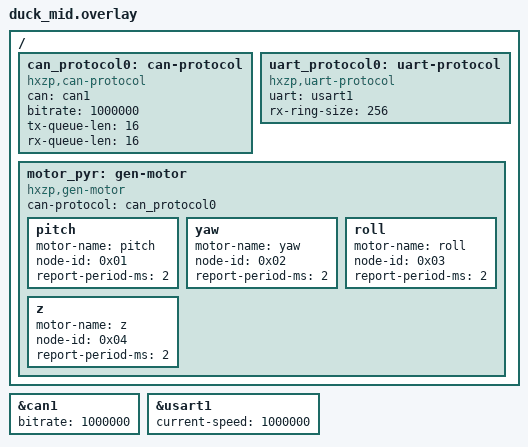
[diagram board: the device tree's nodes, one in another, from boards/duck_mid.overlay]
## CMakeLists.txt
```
# SPDX-License-Identifier: Apache-2.0

cmake_minimum_required(VERSION 3.20.0)

list(APPEND ZEPHYR_EXTRA_MODULES
    ${CMAKE_CURRENT_SOURCE_DIR}/../../zephyr-hxzp
)

find_package(Zephyr REQUIRED HINTS $ENV{ZEPHYR_BASE})
project(duck_mid)

file(GLOB_RECURSE APP_SOURCES CONFIGURE_DEPENDS
    "src/*.c"
    "src/*.cpp"
)

list(FILTER APP_SOURCES EXCLUDE REGEX ".*/src/can_protocol\\.c$")

if(NOT CONFIG_SHELL)
    list(FILTER APP_SOURCES EXCLUDE REGEX ".*/src/debug_shell\\.c$")
endif()

target_sources(app PRIVATE
    ${APP_SOURCES}
)
```

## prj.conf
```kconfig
CONFIG_PRINTK=y
CONFIG_LOG=y

CONFIG_MAIN_STACK_SIZE=2048
CONFIG_STATIC_INIT_GNU=y
# CONFIG_HW_STACK_PROTECTION=y
# C++ 支持
CONFIG_CPP=y
CONFIG_HEAP_MEM_POOL_SIZE=0
CONFIG_THREAD_NAME=n
# 标准库
CONFIG_NEWLIB_LIBC=y
CONFIG_REQUIRES_FULL_LIBC=y

CONFIG_USE_SEGGER_RTT=y
CONFIG_SEGGER_RTT_MAX_NUM_UP_BUFFERS=1
CONFIG_SEGGER_RTT_MAX_NUM_DOWN_BUFFERS=1
CONFIG_SEGGER_RTT_BUFFER_SIZE_UP=1024
CONFIG_SEGGER_RTT_BUFFER_SIZE_DOWN=16

# enable console
CONFIG_CONSOLE=y
# CONFIG_UART_CONSOLE=y
CONFIG_RTT_CONSOLE=y
CONFIG_SHELL=n

CONFIG_LOG_BACKEND_RTT=y
CONFIG_LOG_BACKEND_SHOW_COLOR=n
CONFIG_LOG_BACKEND_RTT_OUTPUT_BUFFER_SIZE=128
CONFIG_LOG_RUNTIME_FILTERING=n
CONFIG_LOG_DEFAULT_LEVEL=3

CONFIG_CAN=y 
# CONFIG_CAN_LOOPBACK=y

CONFIG_HXZP_CAN_PROTOCOL=y
CONFIG_HXZP_GEN_MOTOR=y
CONFIG_HXZP_UART_PROTOCOL=y

# LED Strip 驱动
CONFIG_LED_STRIP=y
CONFIG_WS2812_STRIP_SPI=y

# SPI 驱动
CONFIG_SPI=y

CONFIG_UART_INTERRUPT_DRIVEN=y
CONFIG_DMA=y
CONFIG_DMA_STM32=y
```

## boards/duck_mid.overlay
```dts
&can1 {
	bitrate = <1000000>;
};

&usart1 {
	current-speed = <1000000>;
};

/ {
	can_protocol0: can-protocol {
		compatible = "hxzp,can-protocol";
		status = "okay";
		can = <&can1>;
		bitrate = <1000000>;
		tx-queue-len = <16>;
		rx-queue-len = <16>;
	};

	uart_protocol0: uart-protocol {
		compatible = "hxzp,uart-protocol";
		status = "okay";
		uart = <&usart1>;
		rx-ring-size = <256>;
	};

	motor_pyr: gen-motor {
		compatible = "hxzp,gen-motor";
		status = "okay";
		can-protocol = <&can_protocol0>;

		pitch {
			motor-name = "pitch";
			node-id = <0x01>;
			report-period-ms = <2>;
		};

		yaw {
			motor-name = "yaw";
			node-id = <0x02>;
			report-period-ms = <2>;
		};

		roll {
			motor-name = "roll";
			node-id = <0x03>;
			report-period-ms = <2>;
		};

		z {
			motor-name = "z";
			node-id = <0x04>;
			report-period-ms = <2>;
		};
	};
};
```

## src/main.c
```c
/**
 * @file main.c
 * @brief Duck Mid 应用入口。
 */
#include <zephyr/kernel.h>
#include <zephyr/logging/log.h>

#include "can_command.h"
#include "gimbal.h"
#include "led.h"
#include "motor.h"
#include "uart_command.h"

LOG_MODULE_REGISTER(main_module, LOG_LEVEL_INF);

/** @brief 主循环休眠周期，单位毫秒。 */
#define MAIN_LOOP_SLEEP_MS 20

/**
 * @brief 应用主入口。
 * @return int 始终返回 0。
 * @note 主循环只负责保持系统运行，电机 demo 已移除。
 */
int main(void)
{
    int ret;

    LOG_INF("Hello, Duck!!!");

    ret = led_init();

    if (ret < 0)
    {
        LOG_WRN("LED init failed: %d", ret);
    }
    else
    {
        led_boot_blink();
    }

    ret = uart_command_init();

    if (ret < 0)
    {
        LOG_WRN("UART command init failed: %d", ret);
    }

    ret = motor_init();

    if (ret < 0)
    {
        LOG_WRN("Motor init failed: %d", ret);
    }

    ret = gimbal_init();

    if (ret < 0)
    {
        LOG_WRN("Gimbal init failed: %d", ret);
    }

    ret = can_command_init();

    if (ret < 0)
    {
        LOG_WRN("CAN command init failed: %d", ret);
    }

    while (1)
    {
        k_sleep(K_MSEC(MAIN_LOOP_SLEEP_MS));
    }

    return 0;
}
```

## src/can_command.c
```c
/**
 * @file can_command.c
 * @brief CAN 业务调试命令实现。
 */
#include "can_command.h"

#include "gimbal.h"

#include <errno.h>
#include <stdbool.h>
#include <stdint.h>

#include <zephyr/device.h>
#include <zephyr/devicetree.h>
#include <zephyr/drivers/can.h>
#include <zephyr/drivers/can_protocol.h>
#include <zephyr/kernel.h>
#include <zephyr/logging/log.h>
#include <zephyr/sys/byteorder.h>

LOG_MODULE_REGISTER(can_command, LOG_LEVEL_INF);

/** @brief mid 端云台调试请求 CAN ID。 */
#define CAN_COMMAND_GIMBAL_REQUEST_ID 0x300U

/** @brief mid 端云台调试响应 CAN ID。 */
#define CAN_COMMAND_GIMBAL_RESPONSE_ID 0x301U

/** @brief CAN 业务调试响应负载长度。 */
#define CAN_COMMAND_RESPONSE_DLC 8U

/** @brief CAN 业务调试命令最小负载长度。 */
#define CAN_COMMAND_MIN_DLC 1U

/** @brief CAN 协议设备节点。 */
#define CAN_COMMAND_PROTOCOL_NODE DT_NODELABEL(can_protocol0)

/** @brief PID 字段编号中 loop 字段偏移。 */
#define CAN_COMMAND_PID_LOOP_SHIFT 4U

/** @brief PID 字段编号中 field 字段掩码。 */
#define CAN_COMMAND_PID_FIELD_MASK 0x0FU

/**
 * @brief CAN 业务调试命令码。
 */
enum can_command_gimbal_cmd
{
    /**< 设置单轴目标角度。 */
    CAN_COMMAND_GIMBAL_CMD_SET_AXIS_TARGET = 0x01,
    /**< 关闭云台输出。 */
    CAN_COMMAND_GIMBAL_CMD_DISABLE = 0x02,
    /**< 设置 PID 单个字段。 */
    CAN_COMMAND_GIMBAL_CMD_SET_PID_FIELD = 0x10,
    /**< 读取 PID 单个字段。 */
    CAN_COMMAND_GIMBAL_CMD_GET_PID_FIELD = 0x11,
};

/**
 * @brief CAN 业务调试状态码。
 */
enum can_command_status
{
    /**< 命令成功。 */
    CAN_COMMAND_STATUS_OK = 0x00,
    /**< 命令非法。 */
    CAN_COMMAND_STATUS_INVALID_CMD = 0x01,
    /**< 参数非法。 */
    CAN_COMMAND_STATUS_INVALID_PARAM = 0x02,
    /**< 执行失败。 */
    CAN_COMMAND_STATUS_EXEC_FAILED = 0x03,
};

/**
 * @brief PID 可调字段编号。
 */
enum can_command_pid_field
{
    /**< 比例增益。 */
    CAN_COMMAND_PID_FIELD_KP = 0x00,
    /**< 积分增益。 */
    CAN_COMMAND_PID_FIELD_KI = 0x01,
    /**< 微分增益。 */
    CAN_COMMAND_PID_FIELD_KD = 0x02,
    /**< 积分限幅百分比。 */
    CAN_COMMAND_PID_FIELD_INTEGRAL_LIMIT_PERCENT = 0x03,
    /**< 输出限幅百分比。 */
    CAN_COMMAND_PID_FIELD_OUTPUT_LIMIT_PERCENT = 0x04,
};

/** @brief CAN 协议设备。 */
static const struct device *const can_command_protocol_dev =
    DEVICE_DT_GET(CAN_COMMAND_PROTOCOL_NODE);

/** @brief CAN 业务调试过滤器句柄。 */
static int can_command_filter_handle = -1;

/**
 * @brief 将内部错误码转换为 CAN 业务调试状态码。
 * @param ret 内部错误码。
 * @return uint8_t CAN 业务调试状态码。
 */
static uint8_t can_command_status_from_ret(int ret)
{
    if (ret == 0)
    {
        return CAN_COMMAND_STATUS_OK;
    }

    if ((ret == -EINVAL) || (ret == -EMSGSIZE))
    {
        return CAN_COMMAND_STATUS_INVALID_PARAM;
    }

    return CAN_COMMAND_STATUS_EXEC_FAILED;
}

/**
 * @brief 判断云台轴编号是否有效。
 * @param axis_id 云台轴编号。
 * @return bool true 表示有效，false 表示无效。
 */
static bool can_command_axis_id_is_valid(uint8_t axis_id)
{
    if (axis_id >= (uint8_t)GIMBAL_AXIS_COUNT)
    {
        return false;
    }

    return true;
}

/**
 * @brief 判断 PID 环编号是否有效。
 * @param loop PID 环编号。
 * @return bool true 表示有效，false 表示无效。
 */
static bool can_command_pid_loop_is_valid(uint8_t loop)
{
    if ((loop == (uint8_t)GIMBAL_PID_LOOP_POSITION) ||
        (loop == (uint8_t)GIMBAL_PID_LOOP_SPEED))
    {
        return true;
    }

    return false;
}

/**
 * @brief 判断 PID 字段编号是否有效。
 * @param field PID 字段编号。
 * @return bool true 表示有效，false 表示无效。
 */
static bool can_command_pid_field_is_valid(uint8_t field)
{
    if (field <= (uint8_t)CAN_COMMAND_PID_FIELD_OUTPUT_LIMIT_PERCENT)
    {
        return true;
    }

    return false;
}

/**
 * @brief 从 CAN PID 字段描述中解析 PID 环和字段编号。
 * @param packed CAN PID 字段描述。
 * @param loop 输出 PID 环编号。
 * @param field 输出 PID 字段编号。
 * @return int 0 表示成功，负值表示失败。
 */
static int can_command_parse_pid_selector(uint8_t packed,
                                          enum gimbal_pid_loop *loop,
                                          uint8_t *field)
{
    uint8_t raw_loop;
    uint8_t raw_field;

    if ((loop == NULL) || (field == NULL))
    {
        return -EINVAL;
    }

    raw_loop = packed >> CAN_COMMAND_PID_LOOP_SHIFT;
    raw_field = packed & CAN_COMMAND_PID_FIELD_MASK;

    if (!can_command_pid_loop_is_valid(raw_loop))
    {
        return -EINVAL;
    }

    if (!can_command_pid_field_is_valid(raw_field))
    {
        return -EINVAL;
    }

    *loop = (enum gimbal_pid_loop)raw_loop;
    *field = raw_field;

    return 0;
}

/**
 * @brief 从 PID 百分比配置中读取指定字段。
 * @param config PID 百分比配置。
 * @param field PID 字段编号。
 * @param value 输出字段值。
 * @return int 0 表示成功，负值表示失败。
 */
static int can_command_get_pid_field_value(const struct gimbal_pid_percent_config *config,
                                           uint8_t field,
                                           int32_t *value)
{
    if ((config == NULL) || (value == NULL))
    {
        return -EINVAL;
    }

    switch (field)
    {
    case CAN_COMMAND_PID_FIELD_KP:
        *value = config->kp;
        return 0;

    case CAN_COMMAND_PID_FIELD_KI:
        *value = config->ki;
        return 0;

    case CAN_COMMAND_PID_FIELD_KD:
        *value = config->kd;
        return 0;

    case CAN_COMMAND_PID_FIELD_INTEGRAL_LIMIT_PERCENT:
        *value = (int32_t)config->integral_limit_percent;
        return 0;

    case CAN_COMMAND_PID_FIELD_OUTPUT_LIMIT_PERCENT:
        *value = (int32_t)config->output_limit_percent;
        return 0;

    default:
        break;
    }

    return -EINVAL;
}

/**
 * @brief 向 PID 百分比配置写入指定字段。
 * @param config PID 百分比配置。
 * @param field PID 字段编号。
 * @param value 字段值。
 * @return int 0 表示成功，负值表示失败。
 */
static int can_command_set_pid_field_value(struct gimbal_pid_percent_config *config,
                                           uint8_t field,
                                           int32_t value)
{
    if (config == NULL)
    {
        return -EINVAL;
    }

    switch (field)
    {
    case CAN_COMMAND_PID_FIELD_KP:
        config->kp = value;
        return 0;

    case CAN_COMMAND_PID_FIELD_KI:
        config->ki = value;
        return 0;

    case CAN_COMMAND_PID_FIELD_KD:
        config->kd = value;
        return 0;

    case CAN_COMMAND_PID_FIELD_INTEGRAL_LIMIT_PERCENT:
        if (value < 0)
        {
            return -EINVAL;
        }

        config->integral_limit_percent = (uint32_t)value;
        return 0;

    case CAN_COMMAND_PID_FIELD_OUTPUT_LIMIT_PERCENT:
        if (value < 0)
        {
            return -EINVAL;
        }

        config->output_limit_percent = (uint32_t)value;
        return 0;

    default:
        break;
    }

    return -EINVAL;
}

/**
 * @brief 发送 CAN 业务调试响应。
 * @param cmd 命令码。
 * @param status 状态码。
 * @param axis_id 云台轴编号。
 * @param packed_selector PID 字段描述或保留字段。
 * @param value 响应数值。
 * @return int 0 表示成功，负值表示失败。
 */
static int can_command_send_response(uint8_t cmd,
                                     uint8_t status,
                                     uint8_t axis_id,
                                     uint8_t packed_selector,
                                     int32_t value)
{
    uint8_t payload[CAN_COMMAND_RESPONSE_DLC] = {0};

    payload[0] = cmd;
    payload[1] = status;
    payload[2] = axis_id;
    payload[3] = packed_selector;
    sys_put_le32((uint32_t)value, &payload[4]);

    return can_protocol_send_data(can_command_protocol_dev,
                                  CAN_COMMAND_GIMBAL_RESPONSE_ID,
                                  payload,
                                  CAN_COMMAND_RESPONSE_DLC);
}

/**
 * @brief 处理设置单轴目标角度命令。
 * @param frame CAN 报文。
 * @return int 0 表示成功，负值表示失败。
 */
static int can_command_handle_set_axis_target(const struct can_frame *frame)
{
    uint8_t axis_id;
    int32_t target_mrad;
    int ret;

    if ((frame == NULL) || (frame->dlc < 6U))
    {
        return -EINVAL;
    }

    axis_id = frame->data[1];
    target_mrad = (int32_t)sys_get_le32(&frame->data[2]);

    if (!can_command_axis_id_is_valid(axis_id))
    {
        return -EINVAL;
    }

    ret = gimbal_set_axis_target((enum gimbal_axis_id)axis_id,
                                 target_mrad,
                                 GIMBAL_TARGET_SOURCE_EXTERNAL);

    if (ret < 0)
    {
        return ret;
    }

    return can_command_send_response(frame->data[0],
                                     CAN_COMMAND_STATUS_OK,
                                     axis_id,
                                     0U,
                                     target_mrad);
}

/**
 * @brief 处理关闭云台输出命令。
 * @param frame CAN 报文。
 * @return int 0 表示成功，负值表示失败。
 */
static int can_command_handle_disable(const struct can_frame *frame)
{
    int ret;

    if (frame == NULL)
    {
        return -EINVAL;
    }

    ret = gimbal_disable();

    if (ret < 0)
    {
        return ret;
    }

    return can_command_send_response(frame->data[0],
                                     CAN_COMMAND_STATUS_OK,
                                     0U,
                                     0U,
                                     0);
}

/**
 * @brief 处理设置 PID 单字段命令。
 * @param frame CAN 报文。
 * @return int 0 表示成功，负值表示失败。
 */
static int can_command_handle_set_pid_field(const struct can_frame *frame)
{
    struct gimbal_pid_percent_config config;
    enum gimbal_pid_loop loop;
    uint8_t axis_id;
    uint8_t packed_selector;
    uint8_t field;
    int32_t value;
    int ret;

    if ((frame == NULL) || (frame->dlc < 8U))
    {
        return -EINVAL;
    }

    axis_id = frame->data[1];
    packed_selector = frame->data[2];
    value = (int32_t)sys_get_le32(&frame->data[3]);

    if (!can_command_axis_id_is_valid(axis_id))
    {
        return -EINVAL;
    }

    ret = can_command_parse_pid_selector(packed_selector, &loop, &field);

    if (ret < 0)
    {
        return ret;
    }

    ret = gimbal_get_pid_percent_config((enum gimbal_axis_id)axis_id, loop, &config);

    if (ret < 0)
    {
        return ret;
    }

    ret = can_command_set_pid_field_value(&config, field, value);

    if (ret < 0)
    {
        return ret;
    }

    ret = gimbal_set_pid_percent_config((enum gimbal_axis_id)axis_id, loop, &config);

    if (ret < 0)
    {
        return ret;
    }

    return can_command_send_response(frame->data[0],
                                     CAN_COMMAND_STATUS_OK,
                                     axis_id,
                                     packed_selector,
                                     value);
}

/**
 * @brief 处理读取 PID 单字段命令。
 * @param frame CAN 报文。
 * @return int 0 表示成功，负值表示失败。
 */
static int can_command_handle_get_pid_field(const struct can_frame *frame)
{
    struct gimbal_pid_percent_config config;
    enum gimbal_pid_loop loop;
    uint8_t axis_id;
    uint8_t packed_selector;
    uint8_t field;
    int32_t value;
    int ret;

    if ((frame == NULL) || (frame->dlc < 3U))
    {
        return -EINVAL;
    }

    axis_id = frame->data[1];
    packed_selector = frame->data[2];

    if (!can_command_axis_id_is_valid(axis_id))
    {
        return -EINVAL;
    }

    ret = can_command_parse_pid_selector(packed_selector, &loop, &field);

    if (ret < 0)
    {
        return ret;
    }

    ret = gimbal_get_pid_percent_config((enum gimbal_axis_id)axis_id, loop, &config);

    if (ret < 0)
    {
        return ret;
    }

    ret = can_command_get_pid_field_value(&config, field, &value);

    if (ret < 0)
    {
        return ret;
    }

    return can_command_send_response(frame->data[0],
                                     CAN_COMMAND_STATUS_OK,
                                     axis_id,
                                     packed_selector,
                                     value);
}

/**
 * @brief 处理云台 CAN 业务调试报文。
 * @param frame CAN 报文。
 * @return int 0 表示成功，负值表示失败。
 */
static int can_command_handle_gimbal_frame(const struct can_frame *frame)
{
    if ((frame == NULL) || (frame->dlc < CAN_COMMAND_MIN_DLC))
    {
        return -EINVAL;
    }

    switch (frame->data[0])
    {
    case CAN_COMMAND_GIMBAL_CMD_SET_AXIS_TARGET:
        return can_command_handle_set_axis_target(frame);

    case CAN_COMMAND_GIMBAL_CMD_DISABLE:
        return can_command_handle_disable(frame);

    case CAN_COMMAND_GIMBAL_CMD_SET_PID_FIELD:
        return can_command_handle_set_pid_field(frame);

    case CAN_COMMAND_GIMBAL_CMD_GET_PID_FIELD:
        return can_command_handle_get_pid_field(frame);

    default:
        break;
    }

    return -ENOTSUP;
}

/**
 * @brief CAN 业务调试接收回调。
 * @param frame 接收到的 CAN 报文。
 * @param user_data 用户参数。
 * @return void
 */
static void can_command_rx_handler(const struct can_frame *frame, void *user_data)
{
    uint8_t status;
    uint8_t cmd = 0U;
    uint8_t axis_id = 0U;
    uint8_t packed_selector = 0U;
    int ret;

    ARG_UNUSED(user_data);

    if ((frame != NULL) && (frame->dlc > 0U))
    {
        cmd = frame->data[0];

        if (frame->dlc > 1U)
        {
            axis_id = frame->data[1];
        }

        if (frame->dlc > 2U)
        {
            packed_selector = frame->data[2];
        }
    }

    ret = can_command_handle_gimbal_frame(frame);

    if (ret < 0)
    {
        if (ret == -ENOTSUP)
        {
            status = CAN_COMMAND_STATUS_INVALID_CMD;
        }
        else
        {
            status = can_command_status_from_ret(ret);
        }

        can_command_send_response(cmd, status, axis_id, packed_selector, ret);
    }
}

/**
 * @brief 初始化 CAN 业务调试命令模块。
 * @return int 0 表示成功，负值表示失败。
 */
int can_command_init(void)
{
    struct can_protocol_filter_config filter = {
        .id = CAN_COMMAND_GIMBAL_REQUEST_ID,
        .mask = CAN_STD_ID_MASK,
        .flags = 0U,
    };

    if (!device_is_ready(can_command_protocol_dev))
    {
        return -ENODEV;
    }

    if (can_command_filter_handle >= 0)
    {
        return 0;
    }

    can_command_filter_handle = can_protocol_add_rx_filter(can_command_protocol_dev,
                                                           &filter,
                                                           can_command_rx_handler,
                                                           NULL);

    if (can_command_filter_handle < 0)
    {
        return can_command_filter_handle;
    }

    LOG_INF("CAN gimbal debug ready: req=0x%03x rsp=0x%03x",
            CAN_COMMAND_GIMBAL_REQUEST_ID,
            CAN_COMMAND_GIMBAL_RESPONSE_ID);

    return 0;
}
```

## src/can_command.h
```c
/**
 * @file can_command.h
 * @brief CAN 业务调试命令接口。
 */
#ifndef CAN_COMMAND_H_
#define CAN_COMMAND_H_

#ifdef __cplusplus
extern "C"
{
#endif

/**
 * @brief 初始化 CAN 业务调试命令模块。
 * @return int 0 表示成功，负值表示失败。
 */
int can_command_init(void);

#ifdef __cplusplus
}
#endif

#endif /* CAN_COMMAND_H_ */
```

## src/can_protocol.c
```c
/**
 * @file can_protocol.c
 * @brief CAN 传输层实现。
 */
#include "can_protocol.h"

#include <errno.h>
#include <string.h>

#include <zephyr/device.h>
#include <zephyr/devicetree.h>
#include <zephyr/kernel.h>
#include <zephyr/logging/log.h>

LOG_MODULE_REGISTER(can_protocol, LOG_LEVEL_INF);

/** @brief 默认 CAN 波特率，单位 bit/s。 */
#define CAN_PROTOCOL_BAUDRATE 1000000U

/** @brief 接收消息队列长度。 */
#define CAN_PROTOCOL_RX_QUEUE_LEN 16

/** @brief 发送消息队列长度。 */
#define CAN_PROTOCOL_TX_QUEUE_LEN 16

/** @brief 发送入队等待时间。 */
#define CAN_PROTOCOL_TX_QUEUE_TIMEOUT K_MSEC(100)

/** @brief 发送超时时间。 */
#define CAN_PROTOCOL_TX_TIMEOUT K_MSEC(100)

/** @brief 无效过滤器 ID。 */
#define CAN_PROTOCOL_INVALID_FILTER_ID (-1)

/** @brief 接收线程栈大小。 */
#define CAN_PROTOCOL_THREAD_STACK_SIZE 1024

/** @brief 发送线程栈大小。 */
#define CAN_PROTOCOL_TX_THREAD_STACK_SIZE 1024

/** @brief 接收线程优先级。 */
#define CAN_PROTOCOL_THREAD_PRIORITY 5

/** @brief 发送线程优先级，数值越大优先级越低。 */
#define CAN_PROTOCOL_TX_THREAD_PRIORITY 6

/** @brief CAN 接收消息队列。 */
CAN_MSGQ_DEFINE(can_protocol_rx_msgq, CAN_PROTOCOL_RX_QUEUE_LEN);

/** @brief CAN 发送消息队列。 */
CAN_MSGQ_DEFINE(can_protocol_tx_msgq, CAN_PROTOCOL_TX_QUEUE_LEN);

/** @brief 当前使用的 CAN 控制器设备。 */
static const struct device *const can_dev = DEVICE_DT_GET(DT_NODELABEL(can1));

/** @brief 当前安装的过滤器 ID 列表。 */
static int can_protocol_filter_ids[CAN_PROTOCOL_MAX_FILTER_COUNT];

/** @brief 当前安装的过滤器数量。 */
static size_t can_protocol_filter_count;

/** @brief 接收回调函数。 */
static can_protocol_rx_handler_t can_protocol_rx_handler;

/** @brief 接收回调的用户参数。 */
static void *can_protocol_rx_user_data;

/** @brief 传输层是否已经初始化。 */
static bool can_protocol_initialized;

/** @brief 接收线程是否已经启动。 */
static bool can_protocol_thread_started;

/** @brief 发送线程是否已经启动。 */
static bool can_protocol_tx_thread_started;

/** @brief 传输层互斥锁。 */
K_MUTEX_DEFINE(can_protocol_mutex);

/** @brief 接收线程栈。 */
K_THREAD_STACK_DEFINE(can_protocol_thread_stack, CAN_PROTOCOL_THREAD_STACK_SIZE);

/** @brief 接收线程控制块。 */
static struct k_thread can_protocol_thread_data;

/** @brief 发送线程栈。 */
K_THREAD_STACK_DEFINE(can_protocol_tx_thread_stack, CAN_PROTOCOL_TX_THREAD_STACK_SIZE);

/** @brief 发送线程控制块。 */
static struct k_thread can_protocol_tx_thread_data;

/**
 * @brief 重置过滤器记录。
 * @return void
 */
static void can_protocol_reset_filter_records(void)
{
    size_t i;

    for (i = 0U; i < CAN_PROTOCOL_MAX_FILTER_COUNT; i++)
    {
        can_protocol_filter_ids[i] = CAN_PROTOCOL_INVALID_FILTER_ID;
    }

    can_protocol_filter_count = 0U;
}

/**
 * @brief 移除当前已安装的所有过滤器。
 * @return void
 */
static void can_protocol_remove_filters(void)
{
    size_t i;

    for (i = 0U; i < can_protocol_filter_count; i++)
    {
        if (can_protocol_filter_ids[i] >= 0)
        {
            can_remove_rx_filter(can_dev, can_protocol_filter_ids[i]);
            can_protocol_filter_ids[i] = CAN_PROTOCOL_INVALID_FILTER_ID;
        }
    }

    can_protocol_filter_count = 0U;
}

/**
 * @brief 安装 CAN 接收过滤器。
 * @param filters 过滤器配置列表。
 * @param filter_count 过滤器数量。
 * @return int 0 表示成功，负值表示失败。
 */
static int can_protocol_add_filters(const struct can_protocol_filter_config *filters,
                                    size_t filter_count)
{
    size_t i;

    can_protocol_reset_filter_records();

    for (i = 0U; i < filter_count; i++)
    {
        const struct can_filter filter = {
            .id = filters[i].id,
            .mask = filters[i].mask,
            .flags = filters[i].flags,
        };
        int ret;

        ret = can_add_rx_filter_msgq(can_dev, &can_protocol_rx_msgq, &filter);

        if (ret < 0)
        {
            can_protocol_remove_filters();
            return ret;
        }

        can_protocol_filter_ids[i] = ret;
        can_protocol_filter_count++;
    }

    return 0;
}

/**
 * @brief CAN 控制器状态变化回调。
 * @param dev CAN 设备指针。
 * @param state 新的总线状态。
 * @param err_cnt 当前总线错误计数。
 * @param user_data 用户参数。
 * @return void
 */
static void can_protocol_state_change_cb(const struct device *dev,
                                         enum can_state state,
                                         struct can_bus_err_cnt err_cnt,
                                         void *user_data)
{
    ARG_UNUSED(dev);
    ARG_UNUSED(user_data);

    LOG_WRN("CAN state changed: state=%d tx_err=%u rx_err=%u",
            state,
            err_cnt.tx_err_cnt,
            err_cnt.rx_err_cnt);
}

/**
 * @brief CAN 接收线程入口。
 * @param arg1 线程参数 1。
 * @param arg2 线程参数 2。
 * @param arg3 线程参数 3。
 * @return void
 */
static void can_protocol_thread_entry(void *arg1, void *arg2, void *arg3)
{
    ARG_UNUSED(arg1);
    ARG_UNUSED(arg2);
    ARG_UNUSED(arg3);

    while (1)
    {
        struct can_frame frame;
        can_protocol_rx_handler_t rx_handler;
        void *user_data;

        if (k_msgq_get(&can_protocol_rx_msgq, &frame, K_FOREVER) != 0)
        {
            continue;
        }

        k_mutex_lock(&can_protocol_mutex, K_FOREVER);

        if (!can_protocol_initialized || (can_protocol_rx_handler == NULL))
        {
            k_mutex_unlock(&can_protocol_mutex);
            continue;
        }

        rx_handler = can_protocol_rx_handler;
        user_data = can_protocol_rx_user_data;
        k_mutex_unlock(&can_protocol_mutex);

        rx_handler(&frame, user_data);
    }
}

/**
 * @brief CAN 发送线程入口。
 * @param arg1 线程参数 1。
 * @param arg2 线程参数 2。
 * @param arg3 线程参数 3。
 * @return void
 */
static void can_protocol_tx_thread_entry(void *arg1, void *arg2, void *arg3)
{
    ARG_UNUSED(arg1);
    ARG_UNUSED(arg2);
    ARG_UNUSED(arg3);

    while (1)
    {
        struct can_frame frame;
        bool initialized;
        int ret;

        if (k_msgq_get(&can_protocol_tx_msgq, &frame, K_FOREVER) != 0)
        {
            continue;
        }

        k_mutex_lock(&can_protocol_mutex, K_FOREVER);
        initialized = can_protocol_initialized;
        k_mutex_unlock(&can_protocol_mutex);

        if (!initialized)
        {
            continue;
        }

        ret = can_send(can_dev, &frame, CAN_PROTOCOL_TX_TIMEOUT, NULL, NULL);

        if (ret < 0)
        {
            LOG_ERR("CAN send failed: id=0x%03x ret=%d", frame.id, ret);
        }
    }
}

/**
 * @brief 启动 CAN 接收线程。
 * @return int 0 表示成功，负值表示失败。
 */
static int can_protocol_start_thread(void)
{
    if (can_protocol_thread_started)
    {
        return 0;
    }

    k_thread_create(&can_protocol_thread_data,
                    can_protocol_thread_stack,
                    K_THREAD_STACK_SIZEOF(can_protocol_thread_stack),
                    can_protocol_thread_entry,
                    NULL,
                    NULL,
                    NULL,
                    CAN_PROTOCOL_THREAD_PRIORITY,
                    0,
                    K_NO_WAIT);

    can_protocol_thread_started = true;
    return 0;
}

/**
 * @brief 启动 CAN 发送线程。
 * @return int 0 表示成功，负值表示失败。
 */
static int can_protocol_start_tx_thread(void)
{
    if (can_protocol_tx_thread_started)
    {
        return 0;
    }

    k_thread_create(&can_protocol_tx_thread_data,
                    can_protocol_tx_thread_stack,
                    K_THREAD_STACK_SIZEOF(can_protocol_tx_thread_stack),
                    can_protocol_tx_thread_entry,
                    NULL,
                    NULL,
                    NULL,
                    CAN_PROTOCOL_TX_THREAD_PRIORITY,
                    0,
                    K_NO_WAIT);

    can_protocol_tx_thread_started = true;
    return 0;
}

/**
 * @brief 初始化 CAN 传输层。
 * @param filters 过滤器配置列表。
 * @param filter_count 过滤器数量。
 * @param rx_handler 接收回调函数。
 * @param user_data 传递给接收回调的用户参数。
 * @return int 0 表示成功，负值表示失败。
 */
int can_protocol_init(const struct can_protocol_filter_config *filters,
                      size_t filter_count,
                      can_protocol_rx_handler_t rx_handler,
                      void *user_data)
{
    int ret;

    if ((filters == NULL) || (filter_count == 0U) ||
        (filter_count > CAN_PROTOCOL_MAX_FILTER_COUNT) ||
        (rx_handler == NULL))
    {
        return -EINVAL;
    }

    if (!device_is_ready(can_dev))
    {
        return -ENODEV;
    }

    ret = can_protocol_start_thread();

    if (ret < 0)
    {
        return ret;
    }

    ret = can_protocol_start_tx_thread();

    if (ret < 0)
    {
        return ret;
    }

    if (can_protocol_initialized)
    {
        can_protocol_deinit();
    }

    k_mutex_lock(&can_protocol_mutex, K_FOREVER);
    can_protocol_rx_handler = rx_handler;
    can_protocol_rx_user_data = user_data;
    can_protocol_initialized = false;
    k_msgq_purge(&can_protocol_rx_msgq);
    k_msgq_purge(&can_protocol_tx_msgq);
    can_protocol_reset_filter_records();
    k_mutex_unlock(&can_protocol_mutex);

    ret = can_stop(can_dev);

    if ((ret < 0) && (ret != -EALREADY))
    {
        return ret;
    }

    /*
     * CAN_MODE_NORMAL 不包含 CAN_MODE_ONE_SHOT，控制器会保持自动重传。
     */
    ret = can_set_mode(can_dev, CAN_MODE_NORMAL);

    if (ret < 0)
    {
        return ret;
    }

    ret = can_set_bitrate(can_dev, CAN_PROTOCOL_BAUDRATE);

    if (ret < 0)
    {
        return ret;
    }

    can_set_state_change_callback(can_dev, can_protocol_state_change_cb, NULL);

    ret = can_start(can_dev);

    if (ret < 0)
    {
        can_set_state_change_callback(can_dev, NULL, NULL);
        return ret;
    }

    ret = can_protocol_add_filters(filters, filter_count);

    if (ret < 0)
    {
        can_set_state_change_callback(can_dev, NULL, NULL);
        can_stop(can_dev);
        return ret;
    }

    k_mutex_lock(&can_protocol_mutex, K_FOREVER);
    can_protocol_initialized = true;
    k_mutex_unlock(&can_protocol_mutex);

    LOG_INF("CAN transport init done: bitrate=%u filters=%u tx_queue=%u",
            CAN_PROTOCOL_BAUDRATE,
            (unsigned int)filter_count,
            CAN_PROTOCOL_TX_QUEUE_LEN);

    return 0;
}

/**
 * @brief 反初始化 CAN 传输层。
 * @return void
 */
void can_protocol_deinit(void)
{
    k_mutex_lock(&can_protocol_mutex, K_FOREVER);
    can_protocol_initialized = false;
    can_protocol_rx_handler = NULL;
    can_protocol_rx_user_data = NULL;
    k_mutex_unlock(&can_protocol_mutex);

    can_protocol_remove_filters();
    can_set_state_change_callback(can_dev, NULL, NULL);
    can_stop(can_dev);
    k_msgq_purge(&can_protocol_rx_msgq);
    k_msgq_purge(&can_protocol_tx_msgq);

    k_mutex_lock(&can_protocol_mutex, K_FOREVER);
    can_protocol_reset_filter_records();
    k_mutex_unlock(&can_protocol_mutex);
}

/**
 * @brief 将 CAN 报文放入发送队列。
 * @param frame 待发送的 CAN 报文指针。
 * @return int 0 表示成功放入队列，负值表示失败。
 */
int can_protocol_send(const struct can_frame *frame)
{
    bool initialized;
    int ret;

    if (frame == NULL)
    {
        return -EINVAL;
    }

    if (frame->dlc > CAN_MAX_DLC)
    {
        return -EMSGSIZE;
    }

    k_mutex_lock(&can_protocol_mutex, K_FOREVER);
    initialized = can_protocol_initialized;
    k_mutex_unlock(&can_protocol_mutex);

    if (!initialized)
    {
        return -ENODEV;
    }

    ret = k_msgq_put(&can_protocol_tx_msgq,
                     frame,
                     CAN_PROTOCOL_TX_QUEUE_TIMEOUT);

    if (ret < 0)
    {
        LOG_ERR("CAN tx queue put failed: id=0x%03x ret=%d", frame->id, ret);
    }

    return ret;
}

/**
 * @brief 将标准帧数据报文放入发送队列。
 * @param id 标准帧 ID。
 * @param data 待发送的数据指针。
 * @param dlc 数据长度。
 * @return int 0 表示成功放入队列，负值表示失败。
 */
int can_protocol_send_data(uint32_t id,
                           const uint8_t *data,
                           uint8_t dlc)
{
    struct can_frame frame;

    if ((data == NULL) && (dlc > 0U))
    {
        return -EINVAL;
    }

    if (dlc > CAN_MAX_DLC)
    {
        return -EMSGSIZE;
    }

    memset(&frame, 0, sizeof(frame));
    frame.id = id;
    frame.dlc = dlc;
    frame.flags = 0U;

    if (dlc > 0U)
    {
        memcpy(frame.data, data, dlc);
    }

    return can_protocol_send(&frame);
}
```

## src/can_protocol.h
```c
/**
 * @file can_protocol.h
 * @brief 兼容旧工程 include 路径的 CAN 传输层接口。
 */
#ifndef CAN_PROTOCOL_H_
#define CAN_PROTOCOL_H_

#include <zephyr/drivers/can_protocol.h>

#endif /* CAN_PROTOCOL_H_ */
```

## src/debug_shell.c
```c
/**
 * @file debug_shell.c
 * @brief Duck Mid 调试 shell 命令。
 */
#include <errno.h>
#include <inttypes.h>
#include <stddef.h>
#include <stdint.h>
#include <string.h>

#include <zephyr/device.h>
#include <zephyr/devicetree.h>
#include <zephyr/drivers/gen_motor.h>
#include <zephyr/kernel.h>
#include <zephyr/shell/shell.h>

#include "gimbal.h"

/** @brief gen-motor 设备节点。 */
#define DEBUG_SHELL_GEN_MOTOR_NODE DT_NODELABEL(motor_pyr)

/** @brief 调试 shell 使用的 gen-motor 设备。 */
static const struct device *const debug_shell_gen_motor_dev =
    DEVICE_DT_GET(DEBUG_SHELL_GEN_MOTOR_NODE);

/**
 * @brief 解析有符号 32 位整数。
 * @param text 输入字符串。
 * @param value 输出数值。
 * @return int 0 表示成功，负值表示失败。
 */
static int debug_shell_parse_i32(const char *text, int32_t *value)
{
    int64_t parsed = 0;
    int sign = 1;
    size_t i = 0U;

    if ((text == NULL) || (value == NULL))
    {
        return -EINVAL;
    }

    if (text[0] == '-')
    {
        sign = -1;
        i = 1U;
    }

    if (text[i] == '\0')
    {
        return -EINVAL;
    }

    while (text[i] != '\0')
    {
        if ((text[i] < '0') || (text[i] > '9'))
        {
            return -EINVAL;
        }

        parsed = (parsed * 10) + (text[i] - '0');

        if ((sign > 0) && (parsed > INT32_MAX))
        {
            return -ERANGE;
        }

        if ((sign < 0) && (-parsed < INT32_MIN))
        {
            return -ERANGE;
        }

        i++;
    }

    *value = (int32_t)(parsed * sign);

    return 0;
}

/**
 * @brief 解析无符号 32 位整数。
 * @param text 输入字符串。
 * @param value 输出数值。
 * @return int 0 表示成功，负值表示失败。
 */
static int debug_shell_parse_u32(const char *text, uint32_t *value)
{
    uint64_t parsed = 0U;
    size_t i = 0U;

    if ((text == NULL) || (value == NULL))
    {
        return -EINVAL;
    }

    if (text[0] == '\0')
    {
        return -EINVAL;
    }

    while (text[i] != '\0')
    {
        if ((text[i] < '0') || (text[i] > '9'))
        {
            return -EINVAL;
        }

        parsed = (parsed * 10U) + (uint64_t)(text[i] - '0');

        if (parsed > UINT32_MAX)
        {
            return -ERANGE;
        }

        i++;
    }

    *value = (uint32_t)parsed;

    return 0;
}

/**
 * @brief 按名称解析云台轴。
 * @param text 输入字符串。
 * @param axis_id 输出云台轴编号。
 * @return int 0 表示成功，负值表示失败。
 */
static int debug_shell_parse_axis(const char *text, enum gimbal_axis_id *axis_id)
{
    if ((text == NULL) || (axis_id == NULL))
    {
        return -EINVAL;
    }

    if (strcmp(text, "roll") == 0)
    {
        *axis_id = GIMBAL_AXIS_ROLL;
        return 0;
    }

    if (strcmp(text, "pitch") == 0)
    {
        *axis_id = GIMBAL_AXIS_PITCH;
        return 0;
    }

    if (strcmp(text, "yaw") == 0)
    {
        *axis_id = GIMBAL_AXIS_YAW;
        return 0;
    }

    return -EINVAL;
}

/**
 * @brief 按名称解析 PID 环。
 * @param text 输入字符串。
 * @param loop 输出 PID 环类型。
 * @return int 0 表示成功，负值表示失败。
 */
static int debug_shell_parse_pid_loop(const char *text, enum gimbal_pid_loop *loop)
{
    if ((text == NULL) || (loop == NULL))
    {
        return -EINVAL;
    }

    if (strcmp(text, "pos") == 0)
    {
        *loop = GIMBAL_PID_LOOP_POSITION;
        return 0;
    }

    if (strcmp(text, "position") == 0)
    {
        *loop = GIMBAL_PID_LOOP_POSITION;
        return 0;
    }

    if (strcmp(text, "speed") == 0)
    {
        *loop = GIMBAL_PID_LOOP_SPEED;
        return 0;
    }

    return -EINVAL;
}

/**
 * @brief 获取轴名称。
 * @param axis_id 云台轴编号。
 * @return const char * 轴名称。
 */
static const char *debug_shell_axis_name(enum gimbal_axis_id axis_id)
{
    if (axis_id == GIMBAL_AXIS_ROLL)
    {
        return "roll";
    }

    if (axis_id == GIMBAL_AXIS_PITCH)
    {
        return "pitch";
    }

    if (axis_id == GIMBAL_AXIS_YAW)
    {
        return "yaw";
    }

    return "unknown";
}

/**
 * @brief 获取 PID 环名称。
 * @param loop PID 环类型。
 * @return const char * PID 环名称。
 */
static const char *debug_shell_pid_loop_name(enum gimbal_pid_loop loop)
{
    if (loop == GIMBAL_PID_LOOP_POSITION)
    {
        return "pos";
    }

    if (loop == GIMBAL_PID_LOOP_SPEED)
    {
        return "speed";
    }

    return "unknown";
}

/**
 * @brief 打印单个电机状态。
 * @param shell shell 对象。
 * @param index 电机索引。
 * @return int 0 表示成功，负值表示失败。
 */
static int debug_shell_print_motor_state(const struct shell *shell, size_t index)
{
    const struct gen_motor *motor;
    struct gen_motor_state state;
    int ret;

    motor = gen_motor_get_by_index(debug_shell_gen_motor_dev, index);

    if (motor == NULL)
    {
        shell_error(shell, "m%u missing", (unsigned int)index);
        return -ENODEV;
    }

    ret = gen_motor_copy_state(motor, &state);

    if (ret < 0)
    {
        shell_error(shell, "m%u read %d", (unsigned int)index, ret);
        return ret;
    }

    shell_print(shell,
                "motor %u: pos=%" PRId32 " pos_valid=%u speed=%" PRId32 " speed_valid=%u",
                (unsigned int)index,
                state.position_valid ? state.position_mrad : 0,
                state.position_valid ? 1U : 0U,
                state.speed_valid ? state.speed_mrad_s : 0,
                state.speed_valid ? 1U : 0U);

    return 0;
}

/**
 * @brief shell 命令：打印三个电机位置和速度。
 * @param shell shell 对象。
 * @param argc 参数数量。
 * @param argv 参数数组。
 * @return int 0 表示成功，负值表示失败。
 */
static int debug_shell_cmd_motor_pos(const struct shell *shell, size_t argc, char **argv)
{
    size_t motor_count;
    size_t i;

    ARG_UNUSED(argc);
    ARG_UNUSED(argv);

    if (!device_is_ready(debug_shell_gen_motor_dev))
    {
        shell_error(shell, "motor dev not ready");
        return -ENODEV;
    }

    motor_count = gen_motor_get_count(debug_shell_gen_motor_dev);

    for (i = 0U; i < motor_count; i++)
    {
        debug_shell_print_motor_state(shell, i);
    }

    return 0;
}

/**
 * @brief shell 命令：设置云台目标角。
 * @param shell shell 对象。
 * @param argc 参数数量。
 * @param argv 参数数组。
 * @return int 0 表示成功，负值表示失败。
 */
static int debug_shell_cmd_gimbal_target(const struct shell *shell, size_t argc, char **argv)
{
    int32_t roll_mrad;
    int32_t pitch_mrad;
    int32_t yaw_mrad;
    int ret;

    ARG_UNUSED(argc);

    ret = debug_shell_parse_i32(argv[1], &roll_mrad);

    if (ret < 0)
    {
        shell_error(shell, "bad roll");
        return ret;
    }

    ret = debug_shell_parse_i32(argv[2], &pitch_mrad);

    if (ret < 0)
    {
        shell_error(shell, "bad pitch");
        return ret;
    }

    ret = debug_shell_parse_i32(argv[3], &yaw_mrad);

    if (ret < 0)
    {
        shell_error(shell, "bad yaw");
        return ret;
    }

    ret = gimbal_set_rpy_target(roll_mrad,
                                pitch_mrad,
                                yaw_mrad,
                                GIMBAL_TARGET_SOURCE_EXTERNAL);

    if (ret < 0)
    {
        shell_error(shell, "target %d", ret);
        return ret;
    }

    shell_print(shell,
                "gimbal target set: roll=%" PRId32 " pitch=%" PRId32 " yaw=%" PRId32,
                roll_mrad,
                pitch_mrad,
                yaw_mrad);

    return 0;
}

/**
 * @brief shell 命令：关闭云台输出。
 * @param shell shell 对象。
 * @param argc 参数数量。
 * @param argv 参数数组。
 * @return int 0 表示成功，负值表示失败。
 */
static int debug_shell_cmd_gimbal_disable(const struct shell *shell, size_t argc, char **argv)
{
    int ret;

    ARG_UNUSED(argc);
    ARG_UNUSED(argv);

    ret = gimbal_disable();

    if (ret < 0)
    {
        shell_error(shell, "disable %d", ret);
        return ret;
    }

    shell_print(shell, "gimbal disabled");

    return 0;
}

/**
 * @brief 打印指定 PID 配置。
 * @param shell shell 对象。
 * @param axis_id 云台轴编号。
 * @param loop PID 环类型。
 * @param config PID 百分比配置。
 * @return void
 */
static void debug_shell_print_pid_config(const struct shell *shell,
                                         enum gimbal_axis_id axis_id,
                                         enum gimbal_pid_loop loop,
                                         const struct gimbal_pid_percent_config *config)
{
    if (config == NULL)
    {
        return;
    }

    shell_print(shell,
                "pid %s %s: kp=%" PRId32 " ki=%" PRId32 " kd=%" PRId32
                " integral_limit=%u%% output_limit=%u%%",
                debug_shell_axis_name(axis_id),
                debug_shell_pid_loop_name(loop),
                config->kp,
                config->ki,
                config->kd,
                (unsigned int)config->integral_limit_percent,
                (unsigned int)config->output_limit_percent);
}

/**
 * @brief shell 命令：获取 PID 配置。
 * @param shell shell 对象。
 * @param argc 参数数量。
 * @param argv 参数数组。
 * @return int 0 表示成功，负值表示失败。
 */
static int debug_shell_cmd_gimbal_pid_get(const struct shell *shell, size_t argc, char **argv)
{
    struct gimbal_pid_percent_config config;
    enum gimbal_axis_id axis_id;
    enum gimbal_pid_loop loop;
    int ret;

    ARG_UNUSED(argc);

    ret = debug_shell_parse_axis(argv[1], &axis_id);

    if (ret < 0)
    {
        shell_error(shell, "bad axis");
        return ret;
    }

    ret = debug_shell_parse_pid_loop(argv[2], &loop);

    if (ret < 0)
    {
        shell_error(shell, "bad loop");
        return ret;
    }

    ret = gimbal_get_pid_percent_config(axis_id, loop, &config);

    if (ret < 0)
    {
        shell_error(shell, "pid get %d", ret);
        return ret;
    }

    debug_shell_print_pid_config(shell, axis_id, loop, &config);

    return 0;
}

/**
 * @brief shell 命令：设置 PID 配置。
 * @param shell shell 对象。
 * @param argc 参数数量。
 * @param argv 参数数组。
 * @return int 0 表示成功，负值表示失败。
 */
static int debug_shell_cmd_gimbal_pid_set(const struct shell *shell, size_t argc, char **argv)
{
    struct gimbal_pid_percent_config config;
    enum gimbal_axis_id axis_id;
    enum gimbal_pid_loop loop;
    int ret;

    ARG_UNUSED(argc);

    ret = debug_shell_parse_axis(argv[1], &axis_id);

    if (ret < 0)
    {
        shell_error(shell, "bad axis");
        return ret;
    }

    ret = debug_shell_parse_pid_loop(argv[2], &loop);

    if (ret < 0)
    {
        shell_error(shell, "bad loop");
        return ret;
    }

    ret = debug_shell_parse_i32(argv[3], &config.kp);

    if (ret < 0)
    {
        shell_error(shell, "bad kp");
        return ret;
    }

    ret = debug_shell_parse_i32(argv[4], &config.ki);

    if (ret < 0)
    {
        shell_error(shell, "bad ki");
        return ret;
    }

    ret = debug_shell_parse_i32(argv[5], &config.kd);

    if (ret < 0)
    {
        shell_error(shell, "bad kd");
        return ret;
    }

    ret = debug_shell_parse_u32(argv[6], &config.integral_limit_percent);

    if (ret < 0)
    {
        shell_error(shell, "bad ilimit");
        return ret;
    }

    ret = debug_shell_parse_u32(argv[7], &config.output_limit_percent);

    if (ret < 0)
    {
        shell_error(shell, "bad olimit");
        return ret;
    }

    ret = gimbal_set_pid_percent_config(axis_id, loop, &config);

    if (ret < 0)
    {
        shell_error(shell, "pid set %d", ret);
        return ret;
    }

    debug_shell_print_pid_config(shell, axis_id, loop, &config);

    return 0;
}

SHELL_STATIC_SUBCMD_SET_CREATE(debug_shell_motor_cmds,
    SHELL_CMD_ARG(pos, NULL, NULL, debug_shell_cmd_motor_pos, 1, 0),
    SHELL_SUBCMD_SET_END);

SHELL_STATIC_SUBCMD_SET_CREATE(debug_shell_gimbal_pid_cmds,
    SHELL_CMD_ARG(get,
                  NULL,
                  NULL,
                  debug_shell_cmd_gimbal_pid_get,
                  3,
                  0),
    SHELL_CMD_ARG(set,
                  NULL,
                  NULL,
                  debug_shell_cmd_gimbal_pid_set,
                  8,
                  0),
    SHELL_SUBCMD_SET_END);

SHELL_STATIC_SUBCMD_SET_CREATE(debug_shell_gimbal_cmds,
    SHELL_CMD_ARG(pid,
                  &debug_shell_gimbal_pid_cmds,
                  NULL,
                  NULL,
                  1,
                  0),
    SHELL_CMD_ARG(target,
                  NULL,
                  NULL,
                  debug_shell_cmd_gimbal_target,
                  4,
                  0),
    SHELL_CMD_ARG(disable, NULL, NULL, debug_shell_cmd_gimbal_disable, 1, 0),
    SHELL_SUBCMD_SET_END);

SHELL_CMD_REGISTER(motor, &debug_shell_motor_cmds, NULL, NULL);
SHELL_CMD_REGISTER(gimbal, &debug_shell_gimbal_cmds, NULL, NULL);
```

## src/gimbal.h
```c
/**
 * @file gimbal.h
 * @brief 云台控制模块接口。
 */
#ifndef GIMBAL_H_
#define GIMBAL_H_

#include <stdint.h>

#ifdef __cplusplus
extern "C"
{
#endif

/**
 * @brief 云台控制轴编号。
 */
enum gimbal_axis_id
{
    /**< Roll 轴。 */
    GIMBAL_AXIS_ROLL = 0,
    /**< Pitch 轴。 */
    GIMBAL_AXIS_PITCH,
    /**< Yaw 轴。 */
    GIMBAL_AXIS_YAW,
    /**< 云台轴数量。 */
    GIMBAL_AXIS_COUNT,
};

/**
 * @brief 云台目标来源。
 */
enum gimbal_target_source
{
    /**< 未知来源。 */
    GIMBAL_TARGET_SOURCE_UNKNOWN = 0,
    /**< RK 串口来源。 */
    GIMBAL_TARGET_SOURCE_RK_UART,
    /**< 外部业务接口来源。 */
    GIMBAL_TARGET_SOURCE_EXTERNAL,
};

/**
 * @brief 云台 PID 环类型。
 */
enum gimbal_pid_loop
{
    /**< 位置环。 */
    GIMBAL_PID_LOOP_POSITION = 0,
    /**< 速度环。 */
    GIMBAL_PID_LOOP_SPEED,
};

/**
 * @brief 云台 PID 百分比配置。
 */
struct gimbal_pid_percent_config
{
    /**< 比例增益，按控制器内部缩放系数配置。 */
    int32_t kp;
    /**< 积分增益，按控制器内部缩放系数配置。 */
    int32_t ki;
    /**< 微分增益，按控制器内部缩放系数配置。 */
    int32_t kd;
    /**< 积分限幅百分比，0 表示关闭积分。 */
    uint32_t integral_limit_percent;
    /**< 输出限幅百分比，0 表示不限制输出。 */
    uint32_t output_limit_percent;
};

/**
 * @brief 初始化云台控制模块。
 * @return int 0 表示成功，负值表示失败。
 */
int gimbal_init(void);

/**
 * @brief 设置云台 RPY 目标角度。
 * @param roll_mrad Roll 目标角度，单位 mrad。
 * @param pitch_mrad Pitch 目标角度，单位 mrad。
 * @param yaw_mrad Yaw 目标角度，单位 mrad。
 * @param source 目标来源。
 * @return int 0 表示成功，负值表示失败。
 */
int gimbal_set_rpy_target(int32_t roll_mrad,
                          int32_t pitch_mrad,
                          int32_t yaw_mrad,
                          enum gimbal_target_source source);

/**
 * @brief 设置云台单轴目标角度。
 * @param axis_id 云台轴编号。
 * @param target_mrad 目标角度，单位 mrad。
 * @param source 目标来源。
 * @return int 0 表示成功，负值表示失败。
 */
int gimbal_set_axis_target(enum gimbal_axis_id axis_id,
                           int32_t target_mrad,
                           enum gimbal_target_source source);

/**
 * @brief 关闭云台输出并清除控制目标和 PID 状态。
 * @return int 0 表示成功，负值表示失败。
 */
int gimbal_disable(void);

/**
 * @brief 设置指定轴指定环的 PID 百分比配置。
 * @param axis_id 云台轴编号。
 * @param loop PID 环类型。
 * @param config PID 百分比配置。
 * @return int 0 表示成功，负值表示失败。
 */
int gimbal_set_pid_percent_config(enum gimbal_axis_id axis_id,
                                  enum gimbal_pid_loop loop,
                                  const struct gimbal_pid_percent_config *config);

/**
 * @brief 获取指定轴指定环的 PID 百分比配置。
 * @param axis_id 云台轴编号。
 * @param loop PID 环类型。
 * @param config 输出 PID 百分比配置。
 * @return int 0 表示成功，负值表示失败。
 */
int gimbal_get_pid_percent_config(enum gimbal_axis_id axis_id,
                                  enum gimbal_pid_loop loop,
                                  struct gimbal_pid_percent_config *config);

/**
 * @brief 设置 RK 下发的当前姿态角。
 * @param roll_mrad 当前 Roll 姿态角，单位 mrad。
 * @param pitch_mrad 当前 Pitch 姿态角，单位 mrad。
 * @param yaw_mrad 当前 Yaw 姿态角，单位 mrad。
 * @return int 0 表示成功，负值表示失败。
 * @note Roll 和 Pitch 位置环使用该姿态反馈；Yaw 位置环使用电机角度反馈。
 * @note 该接口不更新角速度反馈，速度源配置为 IMU 时请使用 gimbal_set_imu_feedback。
 */
int gimbal_set_attitude_feedback(int32_t roll_mrad,
                                 int32_t pitch_mrad,
                                 int32_t yaw_mrad);

/**
 * @brief 设置 IMU 姿态角和角速度反馈。
 * @param roll_mrad 当前 Roll 姿态角，单位 mrad。
 * @param pitch_mrad 当前 Pitch 姿态角，单位 mrad。
 * @param yaw_mrad 当前 Yaw 姿态角，单位 mrad。
 * @param roll_speed_mrad_s 当前 Roll 角速度，单位 mrad/s。
 * @param pitch_speed_mrad_s 当前 Pitch 角速度，单位 mrad/s。
 * @param yaw_speed_mrad_s 当前 Yaw 角速度，单位 mrad/s。
 * @return int 0 表示成功，负值表示失败。
 */
int gimbal_set_imu_feedback(int32_t roll_mrad,
                            int32_t pitch_mrad,
                            int32_t yaw_mrad,
                            int32_t roll_speed_mrad_s,
                            int32_t pitch_speed_mrad_s,
                            int32_t yaw_speed_mrad_s);

#ifdef __cplusplus
}
#endif

#endif /* GIMBAL_H_ */
```

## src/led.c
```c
/**
 * @file led.c
 * @brief 应用层 LED 控制实现。
 */
#include "led.h"

#include <errno.h>
#include <string.h>

#include <zephyr/device.h>
#include <zephyr/drivers/led_strip.h>
#include <zephyr/kernel.h>
#include <zephyr/sys/util.h>

/** @brief RGB 灯带设备节点。 */
#define LED_RGB_NODE DT_NODELABEL(rgb_led)

/** @brief RGB 灯带灯珠数量。 */
#define LED_RGB_COUNT DT_PROP(LED_RGB_NODE, chain_length)

/** @brief 白灯亮度。 */
#define LED_WHITE_BRIGHTNESS 0x18

/** @brief 开机闪烁次数。 */
#define LED_BOOT_BLINK_COUNT 5

/** @brief 开机亮灯时长，单位毫秒。 */
#define LED_BOOT_ON_MS 50

/** @brief 开机关灯时长，单位毫秒。 */
#define LED_BOOT_OFF_MS 50

/** @brief RGB 灯带设备实例。 */
static const struct device *const led_rgb_dev = DEVICE_DT_GET(LED_RGB_NODE);

/** @brief RGB 灯带像素缓存。 */
static struct led_rgb led_pixels[LED_RGB_COUNT];

/** @brief RGB 灯带是否可用。 */
static bool led_ready;

/**
 * @brief 清空灯带缓存。
 * @return void
 */
static void led_clear_pixels(void)
{
    memset(led_pixels, 0, sizeof(led_pixels));
}

/**
 * @brief 将所有灯珠设置为同一颜色。
 * @param red 红色亮度。
 * @param green 绿色亮度。
 * @param blue 蓝色亮度。
 * @return void
 */
static void led_fill_all(uint8_t red, uint8_t green, uint8_t blue)
{
    size_t i;

    for (i = 0U; i < ARRAY_SIZE(led_pixels); i++)
    {
        led_pixels[i].r = red;
        led_pixels[i].g = green;
        led_pixels[i].b = blue;
    }
}

/**
 * @brief 刷新灯带显示。
 * @return int 0 表示成功，负值表示失败。
 */
static int led_flush(void)
{
    if (!led_ready)
    {
        return -ENODEV;
    }

    return led_strip_update_rgb(led_rgb_dev, led_pixels, ARRAY_SIZE(led_pixels));
}

/**
 * @brief 关闭所有灯珠。
 * @return void
 */
static void led_turn_off(void)
{
    int ret;

    if (!led_ready)
    {
        return;
    }

    led_clear_pixels();
    ret = led_flush();

    if (ret < 0)
    {
        led_ready = false;
    }
}

/**
 * @brief 初始化应用层 LED。
 * @return int 0 表示成功，负值表示失败。
 */
int led_init(void)
{
    int ret;

    if (!device_is_ready(led_rgb_dev))
    {
        return -ENODEV;
    }

    led_ready = true;
    led_clear_pixels();
    ret = led_flush();

    if (ret < 0)
    {
        led_ready = false;
        return ret;
    }

    return 0;
}

/**
 * @brief 执行开机白灯快速闪烁 5 次。
 * @return void
 */
void led_boot_blink(void)
{
    size_t i;
    int ret;

    if (!led_ready)
    {
        return;
    }

    for (i = 0U; i < LED_BOOT_BLINK_COUNT; i++)
    {
        led_fill_all(LED_WHITE_BRIGHTNESS,
                     LED_WHITE_BRIGHTNESS,
                     LED_WHITE_BRIGHTNESS);
        ret = led_flush();

        if (ret < 0)
        {
            led_ready = false;
            return;
        }

        k_sleep(K_MSEC(LED_BOOT_ON_MS));
        led_turn_off();

        if (!led_ready)
        {
            return;
        }

        k_sleep(K_MSEC(LED_BOOT_OFF_MS));
    }
}
```

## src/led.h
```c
/**
 * @file led.h
 * @brief 应用层 LED 控制接口。
 */
#ifndef LED_H_
#define LED_H_

#ifdef __cplusplus
extern "C"
{
#endif

/**
 * @brief 初始化应用层 LED。
 * @return int 0 表示成功，负值表示失败。
 */
int led_init(void);

/**
 * @brief 执行开机白灯快速闪烁 5 次。
 * @return void
 */
void led_boot_blink(void);

#ifdef __cplusplus
}
#endif

#endif /* LED_H_ */
```

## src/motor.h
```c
/**
 * @file motor.h
 * @brief Duck Mid 电机应用管理接口。
 */
#ifndef MOTOR_H
#define MOTOR_H

#ifdef __cplusplus
extern "C" {
#endif

/**
 * @brief 初始化电机应用管理模块。
 * @return int 0 表示成功，负值表示失败。
 */
int motor_init(void);

#ifdef __cplusplus
}
#endif

#endif /* MOTOR_H */
```
